# liliumSOC1_secure register map
Vendor: Nordic Semiconductor; Series: liliumSOC1; File version: 1
CPU: CM33 r0p4, little endian, MPU, FPU, 3 interrupt priority bits, 480 interrupts, 4 SAU regions
Registers are 32-bit, read-write, reset 0x0 unless marked. A register's access mark holds for its fields unless they carry their own. Offsets are from the block's base; [hi:lo] are bit positions; lines under a group give offsets from that group; 'fields as' and 'values as' point back to an identical list.

## CTRLAP_S — Control access port
Base 0xBF002000
0x100 EVENTS_RXREADY — The RXSTATUS is changed to DataPending
  [0] EVENTS_RXREADY
    0=NotGenerated (Event not generated); 1=Generated (Event generated)
0x104 EVENTS_TXDONE — The TXSTATUS is changed to NoDataPending
  [0] EVENTS_TXDONE
    values as EVENTS_RXREADY.EVENTS_RXREADY
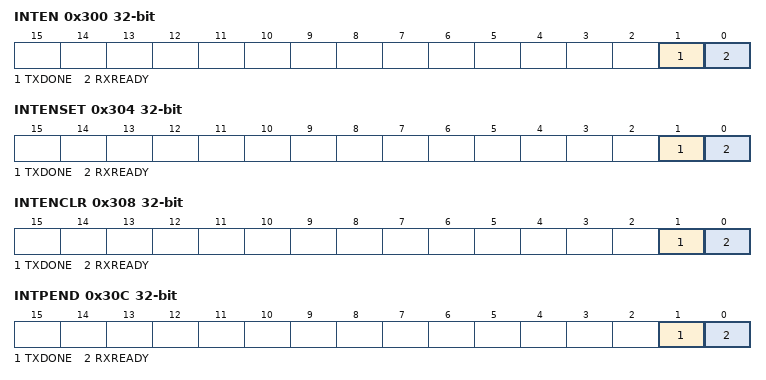
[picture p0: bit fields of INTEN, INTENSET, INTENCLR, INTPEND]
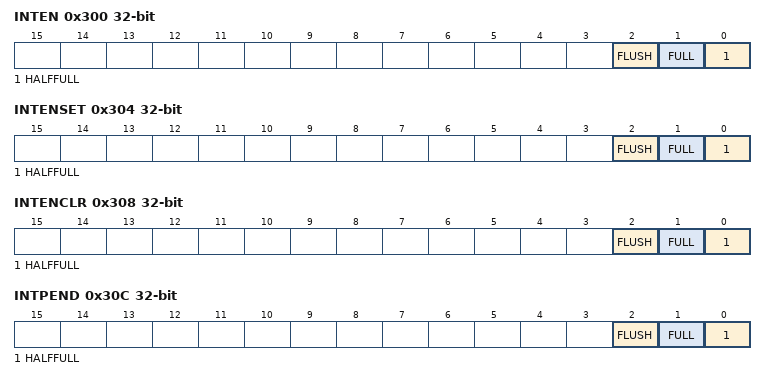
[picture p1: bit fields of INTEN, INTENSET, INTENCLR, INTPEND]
0x300 INTEN — Enable or disable interrupt
  [1] TXDONE — Enable or disable interrupt for event TXDONE
    0=Disabled; 1=Enabled
  [0] RXREADY — Enable or disable interrupt for event RXREADY
    0=Disabled; 1=Enabled
0x304 INTENSET — Enable interrupt
  [1] TXDONE — Write '1' to enable interrupt for event TXDONE
    on read: 0=Disabled (Read: Disabled); 1=Enabled (Read: Enabled) | on write: 1=Set (Enable)
  [0] RXREADY — Write '1' to enable interrupt for event RXREADY
    values as TXDONE
0x308 INTENCLR — Disable interrupt
  [1] TXDONE — Write '1' to disable interrupt for event TXDONE
    on read: 0=Disabled (Read: Disabled); 1=Enabled (Read: Enabled) | on write: 1=Clear (Disable)
  [0] RXREADY — Write '1' to disable interrupt for event RXREADY
    values as TXDONE
0x30C INTPEND ro — Pending interrupts
  [1] TXDONE — Read pending status of interrupt for event TXDONE
    on read: 0=NotPending (Read: Not pending); 1=Pending (Read: Pending)
  [0] RXREADY — Read pending status of interrupt for event RXREADY
    values as TXDONE
0x400 MAILBOX group — Unspecified
  0x00 RXDATA ro — Data sent from the debugger to the CPU
    [31:0] RXDATA — Data received from debugger
  0x04 RXSTATUS ro — Status to indicate if data sent from the debugger to the CPU has been read
    [0] RXSTATUS — Status of data in register RXDATA
      0=No data pending in register RXDATA; 1=Data pending in register RXDATA
  0x80 TXDATA — Data sent from the CPU to the debugger
    [31:0] TXDATA — Data sent to debugger
  0x84 TXSTATUS ro — Status to indicate if data sent from the CPU to the debugger has been read
    [0] TXSTATUS — Status of data in register TXDATA
      0=No data pending in register TXDATA; 1=Data pending in register TXDATA
  0x88 BOOTMODE ro — Secure domain boot mode.
    [0] MODE
      0=Normal mode of operation; 1=ROM operation mode
0x500 INFO group — Unspecified
  0x00 PARTNO — Part number of the device
    [11:0] PARTNO — Part number
  0x04 HWREVISION — Hardware Revision of the device
    [3:0] ID — Part Variant
  0x08 READY reset 0x1 — The INFO registers ready status.
    [0] READY — Ready status.
      0=Ready; 1=NotReady (Not reday)

## GLOBAL_TBM_NS — Trace buffer monitor 0
Base 0xBF003000
Same registers: GLOBAL_TBM_S 0xBF003000 (alternate view of GLOBAL_TBM_NS)
0x00 TASKS_START wo — Start counter
  [0] TASKS_START
    1=Trigger task
0x04 TASKS_STOP wo — Stop counter, clear counter value
  [0] TASKS_STOP
    1=Trigger task
0x08 TASKS_FLUSH wo — Stop counter, keep current counter value
  [0] TASKS_FLUSH
    1=Trigger task
0x100 EVENTS_HALFFULL — Counter value equals half-full
  [0] EVENTS_HALFFULL
    0=NotGenerated (Event not generated); 1=Generated (Event generated)
0x104 EVENTS_FULL — Counter value equals full
  [0] EVENTS_FULL
    values as EVENTS_HALFFULL.EVENTS_HALFFULL
0x108 EVENTS_FLUSH — Counter stopped due to flush
  [0] EVENTS_FLUSH
    values as EVENTS_HALFFULL.EVENTS_HALFFULL
0x200 SHORTS — Shortcuts between local events and tasks
0x300 INTEN — Enable or disable interrupt
  [all] fields
    0=Disabled; 1=Enabled
  [2] FLUSH — Enable or disable interrupt for event FLUSH
  [1] FULL — Enable or disable interrupt for event FULL
  [0] HALFFULL — Enable or disable interrupt for event HALFFULL
0x304 INTENSET — Enable interrupt
  [all] fields
    on read: 0=Disabled (Read: Disabled); 1=Enabled (Read: Enabled) | on write: 1=Set (Enable)
  [2] FLUSH — Write '1' to enable interrupt for event FLUSH
  [1] FULL — Write '1' to enable interrupt for event FULL
  [0] HALFFULL — Write '1' to enable interrupt for event HALFFULL
0x308 INTENCLR — Disable interrupt
  [all] fields
    on read: 0=Disabled (Read: Disabled); 1=Enabled (Read: Enabled) | on write: 1=Clear (Disable)
  [2] FLUSH — Write '1' to disable interrupt for event FLUSH
  [1] FULL — Write '1' to disable interrupt for event FULL
  [0] HALFFULL — Write '1' to disable interrupt for event HALFFULL
0x30C INTPEND ro — Pending interrupts
  [all] fields
    on read: 0=NotPending (Read: Not pending); 1=Pending (Read: Pending)
  [2] FLUSH — Read pending status of interrupt for event FLUSH
  [1] FULL — Read pending status of interrupt for event FULL
  [0] HALFFULL — Read pending status of interrupt for event HALFFULL
0x400 BUFFERSIZE reset 0x1FF — System RAM trace buffer total size in bytes
  [11:0] BUFFERSIZE — Must only be configured in STOP mode. Must be multiple of 16 bytes to make half-buffer size always 64 bit word aligned. BUFFERSIZE LSB byte always fixed as 0xF to 16 bytes boundary. Minimum BUFFERSIZE value 0x00F i.e. 16 bytes, maximum value 0xFFF i.e. 4096 bytes.
    15=Min (16 bytes); 0xFFF=Max (4096 bytes)
0x404 COUNT ro — Counter current value
  [11:0] COUNT
